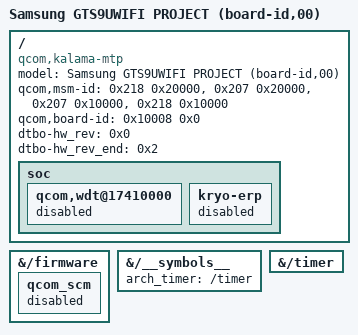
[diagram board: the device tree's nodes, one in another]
/dts-v1/;
/plugin/;

/ {
	model = "Samsung GTS9UWIFI PROJECT (board-id,00)";
	compatible = "qcom,kalama-mtp", "qcom,kalama", "qcom,mtp";
	qcom,msm-id = <0x218 0x20000>, <0x207 0x20000>,
			<0x207 0x10000>, <0x218 0x10000>;
	qcom,board-id = <0x10008 0x0>;
	dtbo-hw_rev = <0x0>;
	dtbo-hw_rev_end = <0x2>;

	fragment@0 {
		target-path = "/";

		__overlay__ {
			/*
			 * Qualcomm's per-boot Gunyah overlay is applied immediately after
			 * this board overlay.  Give it the downstream path anchors it
			 * expects without changing the boot-tested mainline base DTB.
			 */
			soc {
				qcom,wdt@17410000 {
					status = "disabled";
				};

				kryo-erp {
					status = "disabled";
				};
			};
		};
	};

	fragment@1 {
		target-path = "/firmware";

		__overlay__ {
			qcom_scm {
				status = "disabled";
			};
		};
	};

	fragment@2 {
		target-path = "/__symbols__";

		__overlay__ {
			arch_timer = "/timer";
		};
	};

	fragment@3 {
		target-path = "/timer";

		__overlay__ {
			/* Required for the next overlay's arch_timer phandle fixup. */
			phandle = <0x400>;
		};
	};
};
